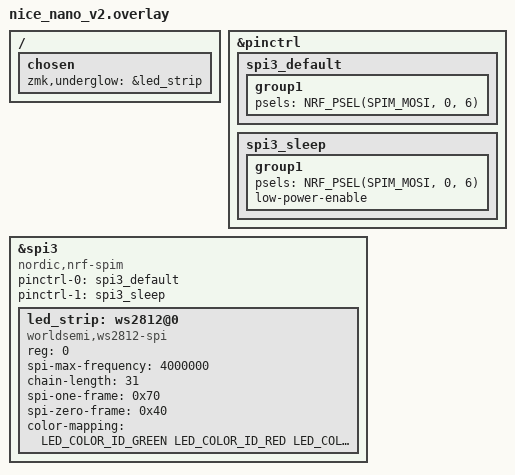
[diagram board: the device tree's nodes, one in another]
/*
#include <dt-bindings/led/led.h>

nice_view_spi: &spi0 {
    pinctrl-0 = <&nice_view_spi_default>;
    pinctrl-1 = <&nice_view_spi_sleep>;
    pinctrl-names = "default", "sleep";
    cs-gpios = <&pro_micro 1 GPIO_ACTIVE_HIGH>;
};

&pinctrl {
    nice_view_spi_default: nice_view_spi_default {
        group1 {
            psels = <NRF_PSEL(SPIM_SCK, 0, 20)>,
                    <NRF_PSEL(SPIM_MOSI, 0, 17)>;
        };
    };
    nice_view_spi_sleep: nice_view_spi_sleep {
        group1 {
            psels = <NRF_PSEL(SPIM_SCK, 0, 20)>,
                    <NRF_PSEL(SPIM_MOSI, 0, 17)>;
            low-power-enable;
        };
    };
};

&pro_micro_i2c {
    status = "disabled";
};
*/
&pinctrl {
    spi3_default: spi3_default {
        group1 {
            psels = <NRF_PSEL(SPIM_MOSI, 0, 6)>;
        };
    };

    spi3_sleep: spi3_sleep {
        group1 {
            psels = <NRF_PSEL(SPIM_MOSI, 0, 6)>;
            low-power-enable;
        };
    };
};

&spi3 {
    compatible = "nordic,nrf-spim";
    status = "okay";

    pinctrl-0 = <&spi3_default>;
    pinctrl-1 = <&spi3_sleep>;
    pinctrl-names = "default", "sleep";

    led_strip: ws2812@0 {
        compatible = "worldsemi,ws2812-spi";

        // SPI
        reg = <0>; // ignored, but necessary for SPI bindings
        spi-max-frequency = <4000000>;

        // WS2812
        chain-length = <31>; // arbitrary; change at will
        spi-one-frame = <0x70>;
        spi-zero-frame = <0x40>;

        color-mapping = <LED_COLOR_ID_GREEN LED_COLOR_ID_RED LED_COLOR_ID_BLUE>;
    };
};

/ {
    chosen {
        zmk,underglow = &led_strip;
    };
};
